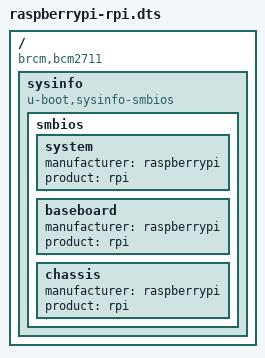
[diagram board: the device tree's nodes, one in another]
// SMBIOS tables support for default Raspberry Pi
/dts-v1/;
/plugin/;

/ {
	compatible = "brcm,bcm2711";
	fragment@0 {
		target-path = "/";
		__overlay__ {
			sysinfo {
				compatible = "u-boot,sysinfo-smbios";
				smbios {
					system {
						manufacturer = "raspberrypi";
						product = "rpi";
					};
					baseboard {
						manufacturer = "raspberrypi";
						product = "rpi";
					};
					chassis {
						manufacturer = "raspberrypi";
						product = "rpi";
					};
				};
			};
		};
	};
};
